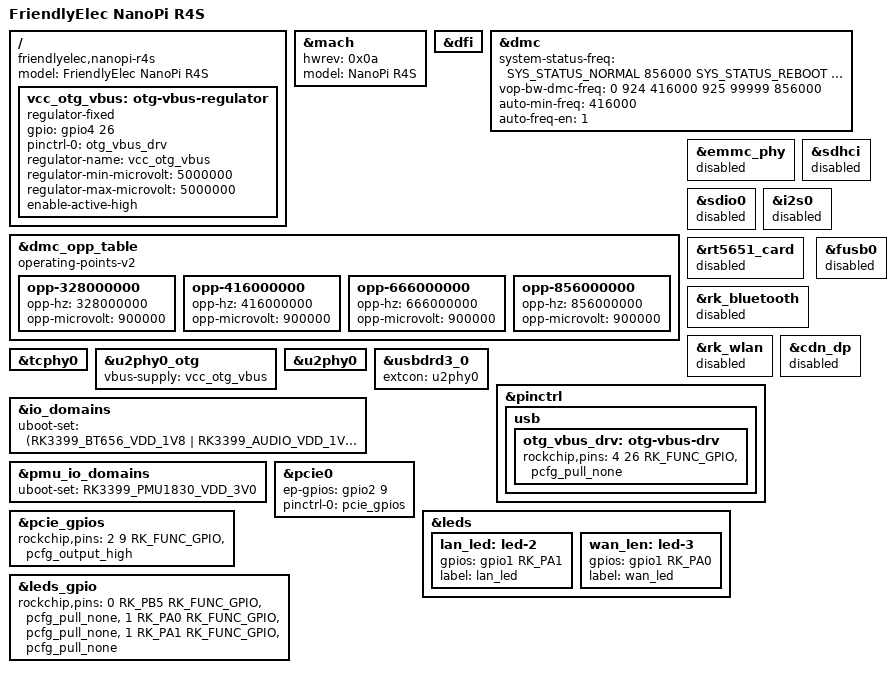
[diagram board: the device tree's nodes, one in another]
/*
 * Copyright (c) 2018 FriendlyElec Computer Tech. Co., Ltd.
 * (http://www.friendlyarm.com)
 *
 * This program is free software; you can redistribute it and/or
 * modify it under the terms of the GNU General Public License
 * as published by the Free Software Foundation; either version 2
 * of the License, or (at your option) any later version.
 *
 * This program is distributed in the hope that it will be useful,
 * but WITHOUT ANY WARRANTY; without even the implied warranty of
 * MERCHANTABILITY or FITNESS FOR A PARTICULAR PURPOSE.  See the
 * GNU General Public License for more details.
 *
 * You should have received a copy of the GNU General Public License
 * along with this program.  If not, see <http://www.gnu.org/licenses/>.
 */

/dts-v1/;
#include <dt-bindings/soc/rockchip-io-domain.h>
#include "rk3399-nanopi4-common.dtsi"

/ {
	model = "FriendlyElec NanoPi R4S";
	compatible = "friendlyelec,nanopi-r4s", "rockchip,rk3399";

	vcc_otg_vbus: otg-vbus-regulator {
		compatible = "regulator-fixed";
		gpio = <&gpio4 26 GPIO_ACTIVE_HIGH>;
		pinctrl-names = "default";
		pinctrl-0 = <&otg_vbus_drv>;
		regulator-name = "vcc_otg_vbus";
		regulator-min-microvolt = <5000000>;
		regulator-max-microvolt = <5000000>;
		enable-active-high;
	};
};

&mach {
	hwrev = <0x0a>;
	model = "NanoPi R4S";
};

&dfi {
	status = "okay";
};

&dmc {
	status = "okay";
	system-status-freq = <
		/*system status         freq(KHz)*/
		SYS_STATUS_NORMAL       856000
		SYS_STATUS_REBOOT       416000
		SYS_STATUS_SUSPEND      416000
		SYS_STATUS_VIDEO_1080P  856000
		SYS_STATUS_VIDEO_4K     856000
		SYS_STATUS_VIDEO_4K_10B 856000
		SYS_STATUS_PERFORMANCE  856000
		SYS_STATUS_BOOST        856000
		SYS_STATUS_DUALVIEW     856000
		SYS_STATUS_ISP          856000
	>;
	vop-bw-dmc-freq = <
	/* min_bw(MB/s) max_bw(MB/s) freq(KHz) */
		0       924      416000
		925     99999    856000
	>;
	auto-min-freq = <416000>;
	auto-freq-en = <1>;
};

&dmc_opp_table {
	compatible = "operating-points-v2";

	/delete-node/ opp-200000000;
	/delete-node/ opp-300000000;
	/delete-node/ opp-400000000;
	/delete-node/ opp-528000000;
	/delete-node/ opp-600000000;
	/delete-node/ opp-800000000;

	opp-328000000 {
		opp-hz = /bits/ 64 <328000000>;
		opp-microvolt = <900000>;
	};
	opp-416000000 {
		opp-hz = /bits/ 64 <416000000>;
		opp-microvolt = <900000>;
	};
	opp-666000000 {
		opp-hz = /bits/ 64 <666000000>;
		opp-microvolt = <900000>;
	};
	opp-856000000 {
		opp-hz = /bits/ 64 <856000000>;
		opp-microvolt = <900000>;
	};
};

&emmc_phy {
	status = "disabled";
};

&sdhci {
	status = "disabled";
};

&sdio0 {
	status = "disabled";
};

&i2s0 {
	status = "disabled";
};

&rt5651_card {
	status = "disabled";
};

&rk_bluetooth {
	status = "disabled";
};

&rk_wlan {
	status = "disabled";
};

&fusb0 {
	status = "disabled";
};

&cdn_dp {
	/delete-property/ extcon;
	status = "disabled";
};

&tcphy0 {
	/delete-property/ extcon;
};

&u2phy0_otg {
	vbus-supply = <&vcc_otg_vbus>;
};

&u2phy0 {
	/delete-property/ extcon;
};

&usbdrd3_0 {
	/delete-property/ extcon;
	extcon = <&u2phy0>;
};

&pinctrl {
	usb {
		otg_vbus_drv: otg-vbus-drv {
			rockchip,pins = <4 26 RK_FUNC_GPIO &pcfg_pull_none>;
		};
	};
};

&io_domains {
	uboot-set = <(RK3399_BT656_VDD_1V8 | RK3399_AUDIO_VDD_1V8 |
		      RK3399_GPIO1833_VDD_3V3)>;
};

&pmu_io_domains {
	uboot-set = <RK3399_PMU1830_VDD_3V0>;
};

&pcie0 {
	ep-gpios = <&gpio2 9 GPIO_ACTIVE_HIGH>;
	pinctrl-names = "default";
	pinctrl-0 = <&pcie_gpios>;
};

&pcie_gpios {
	rockchip,pins =
		<2 9 RK_FUNC_GPIO &pcfg_output_high>;
};

&leds {
	lan_led: led-2 {
		gpios = <&gpio1 RK_PA1 GPIO_ACTIVE_HIGH>;
		label = "lan_led";
	};

	wan_len: led-3 {
		gpios = <&gpio1 RK_PA0 GPIO_ACTIVE_HIGH>;
		label = "wan_led";
	};
};

&leds_gpio {
	rockchip,pins =
		<0 RK_PB5 RK_FUNC_GPIO &pcfg_pull_none>,
		<1 RK_PA0 RK_FUNC_GPIO &pcfg_pull_none>,
		<1 RK_PA1 RK_FUNC_GPIO &pcfg_pull_none>;
};
